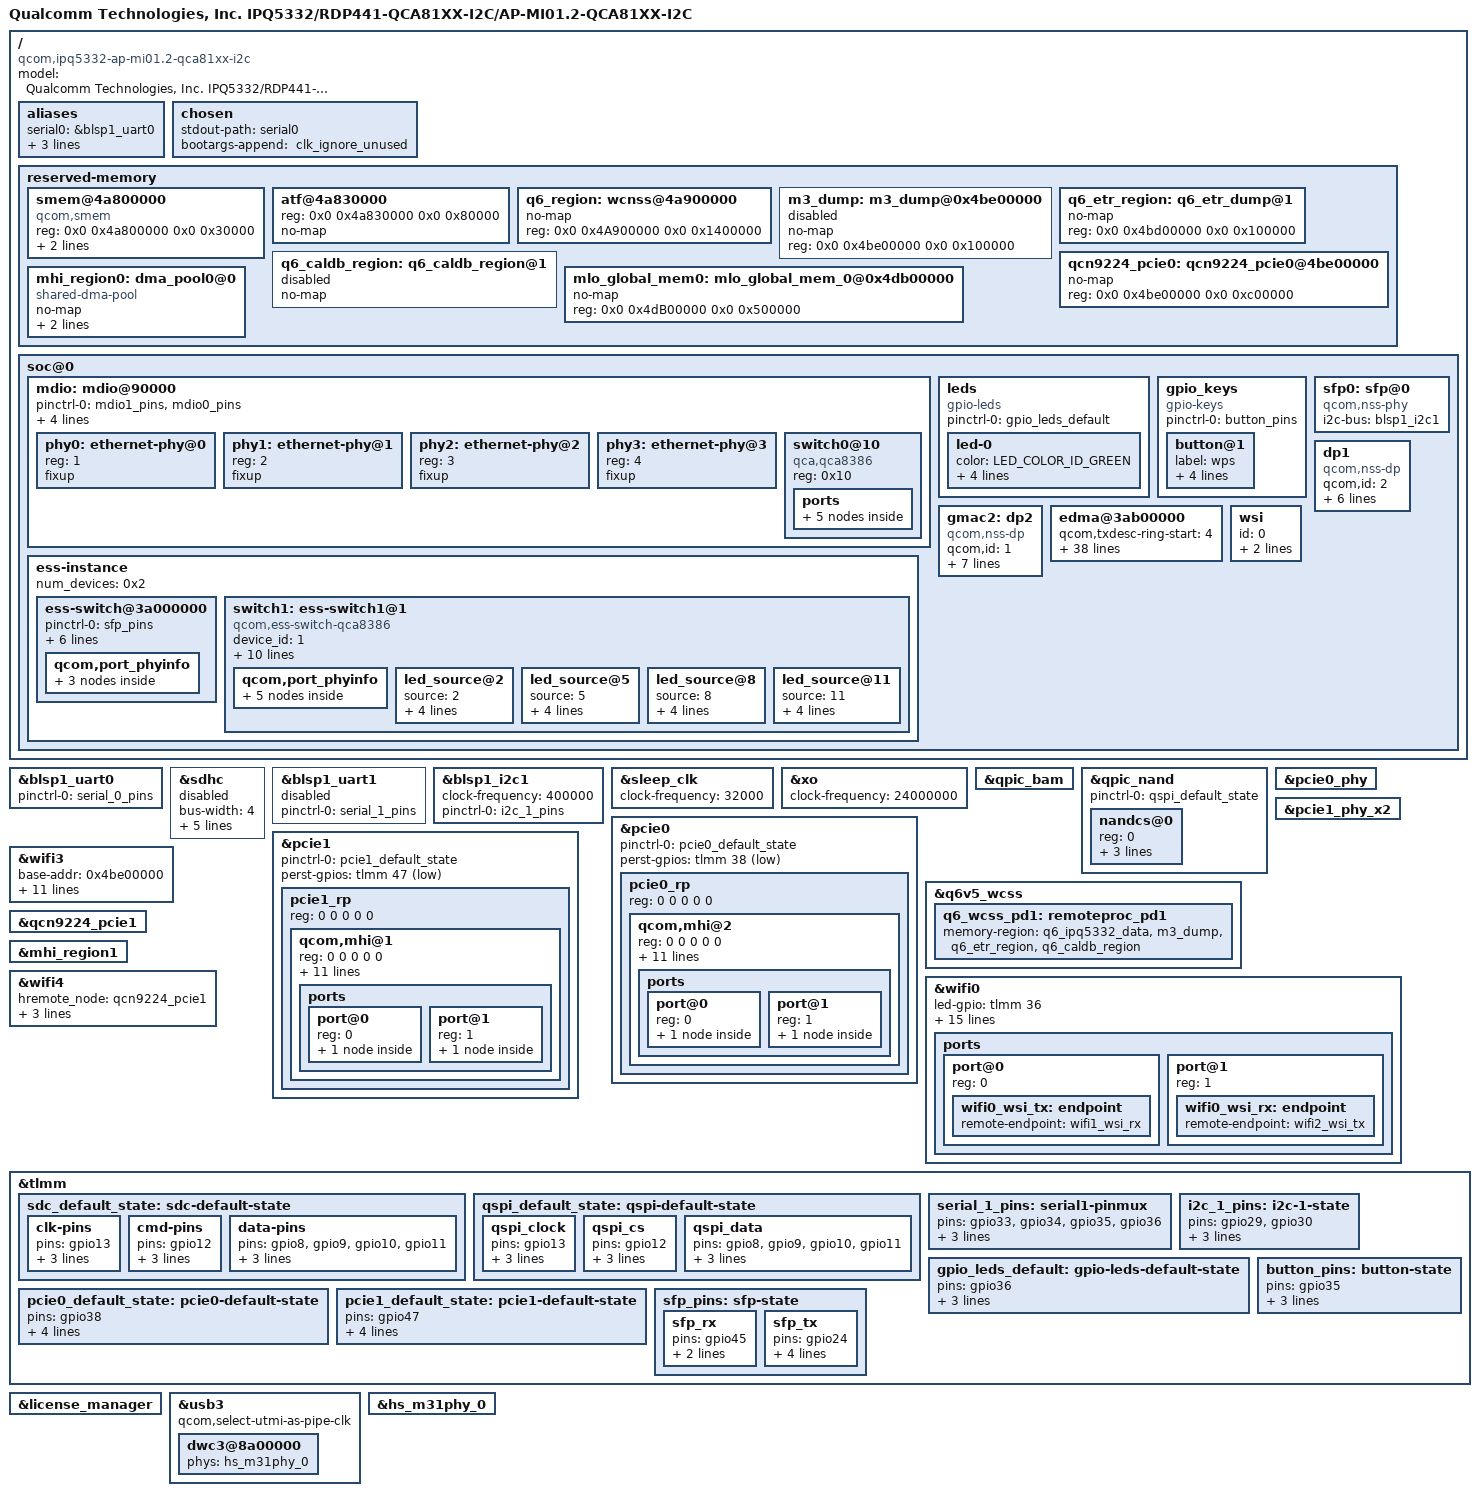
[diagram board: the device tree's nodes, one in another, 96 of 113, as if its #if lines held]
// SPDX-License-Identifier: BSD-3-Clause
/*
 * IPQ5332 AP-MI01.2-QCA81XX-I2C board device tree source
 *
 * Copyright (c) 2022-2025 Qualcomm Innovation Center, Inc. All rights reserved.
 */

/dts-v1/;

#include <dt-bindings/gpio/gpio.h>
#include <dt-bindings/input/input.h>
#include <dt-bindings/leds/common.h>
#include "ipq5332.dtsi"
#ifdef __IPQ_MEM_PROFILE_512_MB__
#include "ipq5332-512MB-memory.dtsi"
#elif !defined(__IPQ_MEM_PROFILE_256_MB__)
#include "ipq5332-default-memory.dtsi"
#endif

/ {
	model = "Qualcomm Technologies, Inc. IPQ5332/RDP441-QCA81XX-I2C/AP-MI01.2-QCA81XX-I2C";
	compatible = "qcom,ipq5332-ap-mi01.2-qca81xx-i2c", "qcom,ipq5332-rdp441-qca81xx-i2c", "qcom,ipq5332";

	aliases {
		serial0 = &blsp1_uart0;
		serial1 = &blsp1_uart1;
		ethernet0 = "/soc/dp1";
		ethernet1 = "/soc/dp2";
	};

	chosen {
		stdout-path = "serial0";
		bootargs-append = " clk_ignore_unused";
	};

#if defined(__IPQ_MEM_PROFILE_256_MB__)
	/*	  256MB Profile for IPQ5322 + QCN9224
	 * +=========+==============+========================+
	 * |        |              |                         |
	 * | Region | Start Offset |          Size           |
	 * |        |              |                         |
	 * +--------+--------------+-------------------------+
	 * |  SMEM  |  0x4A800000  |          192KB          |
	 * +--------+--------------+-------------------------+
	 * |  ATF   |  0x4A830000  |          512KB          |
	 * +--------+--------------+-------------------------+
	 * |       320 KB not-reserved, used by linux        |
	 * +--------+--------------+-------------------------+
	 * | WLAN   |              |                         |
	 * |   Q6   |  0x4A900000  |          20MB           |
	 * +--------+--------------+-------------------------+
	 * |  QDSS  |  0x4BD00000  |           1MB           |
	 * +--------+--------------+-------------------------+
	 * |  WKK0  |  0x4BE00000  |          12MB           |
	 * +--------+--------------+-------------------------+
	 * |       17 MB not-reserved, used by linux         |
	 * +--------+--------------+-------------------------+
	 * |  MLO   |  0x4DB00000  |           5MB           |
	 * +--------+--------------+-------------------------+
	 * |  MHI0  |    DYNAMIC   |           9MB           |
	 * +=================================================+
	 * |                                                 |
	 * |                                                 |
	 * |            Rest of memory for Linux             |
	 * |                                                 |
	 * |                                                 |
	 * +=================================================+
	 */

	reserved-memory {
		/delete-node/ bootloader@4a300000;
		/delete-node/ sbl@4a500000;

		smem@4a800000 {
			compatible = "qcom,smem";
			reg = <0x0 0x4a800000 0x0 0x30000>;
			no-map;
			hwlocks = <&tcsr_mutex 3>;
		};

		atf@4a830000 {
			reg = <0x0 0x4a830000 0x0 0x80000>;
			no-map;
		};

		q6_region: wcnss@4a900000 {
			no-map;
			reg = <0x0 0x4A900000 0x0 0x1400000>;
		};

		m3_dump: m3_dump@0x4be00000 {
			no-map;
			reg = <0x0 0x4be00000 0x0 0x100000>;
			status = "disabled";
		};

		q6_etr_region: q6_etr_dump@1 {
			no-map;
			reg = <0x0 0x4bd00000 0x0 0x100000>;
		};

		q6_caldb_region:q6_caldb_region@1 {
			no-map;
			status = "disabled";
		};

		qcn9224_pcie0: qcn9224_pcie0@4be00000 {
			no-map;
			reg = <0x0 0x4be00000 0x0 0xc00000>;
		};

		mlo_global_mem0: mlo_global_mem_0@0x4db00000 {
			no-map;
			reg = <0x0 0x4dB00000 0x0 0x500000>;
		};

		mhi_region0: dma_pool0@0 {
			compatible = "shared-dma-pool";
			no-map;
			size = <0x0 0x900000>;
			alignment = <0x0 0x1000>;
		};
	};
#endif

	soc@0 {
		mdio:mdio@90000 {
			pinctrl-0 = <&mdio1_pins &mdio0_pins>;
			pinctrl-names = "default";
			/*gpio51 for manhattan reset*/
			phy-reset-gpio = <&tlmm 51 GPIO_ACTIVE_LOW>;
			phyaddr_fixup = <0xC90F018>;
			uniphyaddr_fixup = <0xC90F014>;
			mdio_clk_fixup; /* MDIO clock sequence fix up flag */
			status = "okay";

			phy0: ethernet-phy@0 {
				reg = <1>;
				fixup;
			};
			phy1: ethernet-phy@1 {
				reg = <2>;
				fixup;
			};
			phy2: ethernet-phy@2 {
				reg = <3>;
				fixup;
			};
			phy3: ethernet-phy@3 {
				reg = <4>;
				fixup;
			};

			switch0@10 {
				compatible = "qca,qca8386";
				#address-cells = <1>;
				#size-cells = <0>;
				reg = <0x10>;

				ports {
					#address-cells = <1>;
					#size-cells = <0>;

					port@0 {
						reg = <0>;
						label = "cpu";
						ethernet = <&gmac2>;
						dsa-tag-protocol = "qca_8021q";
					};

					port@1 {
						reg = <1>;
						label = "lan1";
						phy-handle = <&phy0>;
						phy-mode = "internal";
					};

					port@2 {
						reg = <2>;
						label = "lan2";
						phy-handle = <&phy1>;
						phy-mode = "internal";
					};

					port@3 {
						reg = <3>;
						label = "lan3";
						phy-handle = <&phy2>;
						phy-mode = "internal";
					};

					port@4 {
						reg = <4>;
						label = "lan4";
						phy-handle = <&phy3>;
						phy-mode = "internal";
					};
				};
			};
		};

		leds {
			compatible = "gpio-leds";
			pinctrl-0 = <&gpio_leds_default>;
			pinctrl-names = "default";

			led-0 {
				color = <LED_COLOR_ID_GREEN>;
				function = LED_FUNCTION_WLAN;
				gpios = <&tlmm 36 GPIO_ACTIVE_HIGH>;
				linux,default-trigger = "phy0tx";
				default-state = "off";
			};
		};

		gpio_keys {
			compatible = "gpio-keys";
			pinctrl-0 = <&button_pins>;
			pinctrl-names = "default";
			status = "okay";

			button@1 {
				label = "wps";
				linux,code = <KEY_WPS_BUTTON>;
				gpios = <&tlmm 35 GPIO_ACTIVE_LOW>;
				linux,input-type = <1>;
				debounce-interval = <60>;
			};
		};

		sfp0: sfp@0 {
			status = "okay";
			compatible = "qcom,nss-phy";
			i2c-bus = <&blsp1_i2c1>;
		};

		ess-instance {
			num_devices = <0x2>;

			ess-switch@3a000000 {
				pinctrl-0 = <&sfp_pins>;
				pinctrl-names = "default";
				switch_cpu_bmp = <0x1>;  /* cpu port bitmap */
				switch_lan_bmp = <0x2>; /* lan port bitmap */
				switch_wan_bmp = <0x4>; /* wan port bitmap */
				switch_mac_mode = <0xc>; /* mac mode for uniphy instance0*/
				switch_mac_mode1 = <0xe>; /* mac mode for uniphy instance1*/
				switch_mac_mode2 = <0xff>; /* mac mode for uniphy instance2*/

				qcom,port_phyinfo {
					port@0 {
						port_id = <1>;
						forced-speed = <2500>;
						forced-duplex = <1>;
						switch_external {
							switch_handle = <&switch1>;
							switch_cpu_port = <0>;
						};
					};
					port@1 {
						port_id = <2>;
						media-type = "sfp"; /* fiber mode */
						i2c-bus = <&blsp1_i2c1>;
					};
				};
			};

			switch1: ess-switch1@1 {
				compatible = "qcom,ess-switch-qca8386";
				device_id = <1>;
				switch_access_mode = "mdio";
				mdio-bus = <&mdio>;
				switch_mac_mode = <0xc>; /* mac mode for uniphy instance0 */
				switch_mac_mode1 = <0xff>; /* mac mode1 for uniphy instance1 */
				switch_cpu_bmp = <0x1>;  /* cpu port bitmap */
				switch_lan_bmp = <0x1e>; /* lan port bitmap */
				switch_wan_bmp = <0x0>;  /* wan port bitmap */
				link-polling-required = <0>;
				fdb_sync = "interrupt";
				link-intr-gpio = <&tlmm 23 GPIO_ACTIVE_HIGH>;

				qcom,port_phyinfo {
					port@0 {
						port_id = <0>;
						forced-speed = <2500>;
						forced-duplex = <1>;
					};
					port@1 {
						port_id = <1>;
						phy_address = <1>;
					};
					port@2 {
						port_id = <2>;
						phy_address = <2>;
					};
					port@3 {
						port_id = <3>;
						phy_address = <3>;
					};
					port@4 {
						port_id = <4>;
						phy_address = <4>;
					};
				};

				led_source@2 {
					source = <2>;
					mode = "normal";
					speed = "all";
					blink_en = "enable";
					active = "high";
				};
				led_source@5 {
					source = <5>;
					mode = "normal";
					speed = "all";
					blink_en = "enable";
					active = "high";
				};
				led_source@8 {
					source = <8>;
					mode = "normal";
					speed = "all";
					blink_en = "enable";
					active = "high";
				};
				led_source@11 {
					source = <11>;
					mode = "normal";
					speed = "all";
					blink_en = "enable";
					active = "high";
				};
			};
		};

		dp1 {
			device_type = "network";
			compatible = "qcom,nss-dp";
			qcom,id = <2>;
			reg = <0x3a504000 0x4000>;
			qcom,mactype = <1>;
			local-mac-address = [000000000000];
			i2c-bus = <&blsp1_i2c1>;
			qcom,link-poll = <1>;
			phy-mode = "sgmii";
		};

		gmac2:dp2 {
			device_type = "network";
			compatible = "qcom,nss-dp";
			qcom,id = <1>;
			reg = <0x3a500000 0x4000>;
			qcom,mactype = <1>;
			local-mac-address = [000000000000];
			phy-mode = "sgmii";
			qcom,mht-dev = <1>;
			qcom,is_switch_connected = <1>;
			qcom,ppe-offload-disabled = <1>;
		};

		/* EDMA host driver configuration for the board */
		edma@3ab00000 {
			qcom,txdesc-ring-start = <4>;		/* Tx desc ring start ID */
			qcom,txdesc-rings = <12>;		/* Total number of Tx desc rings to be provisioned */
			qcom,mht-txdesc-rings = <8>;            /* Extra Tx desc rings to be provisioned for MHT SW ports */
			qcom,txcmpl-ring-start = <4>;		/* Tx complete ring start ID */
			qcom,txcmpl-rings = <12>;		/* Total number of Tx complete rings to be provisioned */
			qcom,mht-txcmpl-rings = <8>;            /* Extra Tx complete rings to be provisioned for mht sw ports. */
			qcom,rxfill-ring-start = <4>;		/* Rx fill ring start ID */
			qcom,rxfill-rings = <4>;		/* Total number of Rx fill rings to be provisioned */
			qcom,rxdesc-ring-start = <12>;		/* Rx desc ring start ID */
			qcom,rxdesc-rings = <4>;		/* Total number of Rx desc rings to be provisioned */
			qcom,rx-page-mode = <0>;		/* Rx fill ring page mode */
			qcom,tx-map-priority-level = <1>;	/* Tx priority level per port */
			qcom,rx-map-priority-level = <1>;	/* Rx priority level per core */
			qcom,num_loopback_rings = <1>;
			qcom,txdesc_loopback_ring_id = <0>;
			qcom,txcmpl_loopback_ring_id = <0>;
			qcom,rxfill_loopback_ring_id = <0>;
			qcom,rxdesc_loopback_ring_id = <0>;
			qcom,loopback_queue_base = <56>;
			qcom,loopback_num_queues = <8>;
			qcom,ppeds-num = <2>;			/* Number of PPEDS nodes */
			/* PPE-DS node format: <Rx-fill Tx-cmpl Rx Tx Queue-base Queue-count> */
			qcom,ppeds-map = <1 1 1 1 32 8>,	/* PPEDS Node#0 ring and queue map */
					<2 2 2 2 40 8>;		/* PPEDS Node#1 ring and queue map */
			qcom,txdesc-map = <8 9 10 11>,		/* Port0 per-core Tx ring map */
					<12 13 14 15>,        /* MHT-Port1 per-core Tx ring map */
					<4 5 6 7>,            /* MHT-Port2 per-core Tx ring map/packets from  vp*/
					<16 17 18 19>,        /* MHT-Port3 per-core Tx ring map */
					<20 21 22 23>;        /* MHT-Port4 per-core Tx ring map */
			qcom,txdesc-fc-grp-map = <1 2 3 4 5>;   /* Per GMAC flow control group map */
			qcom,rxfill-map = <4 5 6 7>;		/* Per-core Rx fill ring map */
			qcom,rxdesc-map = <12 13 14 15>;	/* Per-core Rx desc ring map */
			qcom,rx-queue-start = <0>;		/* Rx queue start */
			qcom,rx-ring-queue-map = <0 8 16 24>,	/* Priority 0 queues per-core Rx ring map */
						<1 9 17 25>,	/* Priority 1 queues per-core Rx ring map */
						<2 10 18 26>,	/* Priority 2 queues per-core Rx ring map */
						<3 11 19 27>,	/* Priority 3 queues per-core Rx ring map */
						<4 12 20 28>,	/* Priority 4 queues per-core Rx ring map */
						<5 13 21 29>,	/* Priority 5 queues per-core Rx ring map */
						<6 14 22 30>,	/* Priority 6 queues per-core Rx ring map */
						<7 15 23 31>;	/* Priority 7 queues per-core Rx ring map */
			interrupts = <0 163 4>,			/* Tx complete ring id #4 IRQ info */
				   <0 164 4>,			/* Tx complete ring id #5 IRQ info */
				   <0 165 4>,			/* Tx complete ring id #6 IRQ info */
				   <0 166 4>,			/* Tx complete ring id #7 IRQ info */
				   <0 167 4>,			/* Tx complete ring id #8 IRQ info */
				   <0 168 4>,			/* Tx complete ring id #9 IRQ info */
				   <0 169 4>,			/* Tx complete ring id #10 IRQ info */
				   <0 170 4>,			/* Tx complete ring id #11 IRQ info */
				   <0 171 4>,			/* Tx complete ring id #12 IRQ info */
				   <0 172 4>,			/* Tx complete ring id #13 IRQ info */
				   <0 173 4>,			/* Tx complete ring id #14 IRQ info */
				   <0 174 4>,			/* Tx complete ring id #15 IRQ info */
				   <0 139 4>,			/* Rx desc ring id #12 IRQ info */
				   <0 140 4>,			/* Rx desc ring id #13 IRQ info */
				   <0 141 4>,			/* Rx desc ring id #14 IRQ info */
				   <0 142 4>,			/* Rx desc ring id #15 IRQ info */
				   <0 191 4>,			/* Misc error IRQ info */
				   <0 155 4>,			/* RxFill ring id #4 IRQ info */
				   <0 156 4>,			/* RxFill ring id #5 IRQ info */
				   <0 157 4>,			/* RxFill ring id #6 IRQ info */
				   <0 158 4>,			/* RxFill ring id #7 IRQ info */
				<0 160 4>,			/* PPEDS Node #1(TxComp ring id #1) TxComplete IRQ info */
				<0 128 4>,			/* PPEDS Node #1(Rx Desc ring id #1) Rx Desc IRQ info */
				<0 152 4>,			/* PPEDS Node #1(RxFill Desc ring id #1) Rx Fill IRQ info */
				<0 161 4>,			/* PPEDS Node #2(TxComp ring id #2) TxComplete IRQ info */
				<0 129 4>,			/* PPEDS Node #2(Rx Desc ring id #2) Rx Desc IRQ info */
				<0 153 4>,                      /* PPEDS Node #2(RxFill Desc ring id #2) Rx Fill IRQ info */
				<0 175 4>,                   /* MHT port Tx complete ring id #16 IRQ info */
				<0 176 4>,                   /* MHT port Tx complete ring id #17 IRQ info */
				<0 177 4>,                   /* MHT port Tx complete ring id #18 IRQ info */
				<0 178 4>,                   /* MHT port Tx complete ring id #19 IRQ info */
				<0 179 4>,                   /* MHT port Tx complete ring id #20 IRQ info */
				<0 180 4>,                   /* MHT port Tx complete ring id #21 IRQ info */
				<0 181 4>,                   /* MHT port Tx complete ring id #22 IRQ info */
				<0 182 4>;                   /* MHT port Tx complete ring id #23 IRQ info */
		};

		wsi: wsi {
			id = <0>;
			num_chip = <3>;
			status = "okay";
			chip_info = <0 2 1 2>,
				    <1 2 2 0>,
				    <2 2 0 1>;
		};
	};
};

&blsp1_uart0 {
	pinctrl-0 = <&serial_0_pins>;
	pinctrl-names = "default";
	status = "okay";
};

&sdhc {
	bus-width = <4>;
	max-frequency = <192000000>;
	mmc-ddr-1_8v;
	mmc-hs200-1_8v;
	non-removable;
	pinctrl-0 = <&sdc_default_state>;
	pinctrl-names = "default";
	status = "disabled";
};

&blsp1_uart1 {
	pinctrl-0 = <&serial_1_pins>;
	pinctrl-names = "default";
	status = "disabled";
};

&blsp1_i2c1 {
	clock-frequency  = <400000>;
	pinctrl-0 = <&i2c_1_pins>;
	pinctrl-names = "default";
	status = "okay";
};

&sleep_clk {
	clock-frequency = <32000>;
};

&xo {
	clock-frequency = <24000000>;
};

&qpic_bam {
	status = "okay";
};

&qpic_nand {
	pinctrl-0 = <&qspi_default_state>;
	pinctrl-names = "default";
	status = "okay";

	nandcs@0 {
		reg = <0>;
		#address-cells = <1>;
		#size-cells = <1>;

		nand-ecc-strength = <8>;
		nand-ecc-step-size = <512>;
		nand-bus-width = <8>;
	};
};

&pcie0_phy {
	status = "okay";
};

&pcie0 {
	pinctrl-0 = <&pcie0_default_state>;
	pinctrl-names = "default";
	perst-gpios = <&tlmm 38 GPIO_ACTIVE_LOW>;
	status = "okay";

	pcie0_rp {
		reg = <0 0 0 0 0>;

		qcom,mhi@2 {
			reg = <0 0 0 0 0>;
			boot-args = <0x2 0x4 0x34 0x3 0x0 0x0     /* MX Rail, GPIO52, Drive strength 0x3 */
					0x4 0x4 0x18 0x3 0x0 0x0  /* RFA1p2 Rail, GPIO24, Drive strength 0x3 */
					0x0 0x4 0x0 0x0 0x0 0x0>; /* End of arguments */
			memory-region = <&qcn9224_pcie0>, <&mhi_region0>, <&mlo_global_mem0>;
			memory-region-names = "host-ddr-mem", "mhi-region", "mlo-global-mem";
			qcom,early_cal_enabled = "supported";
			qcom,caldata_offset = <0x26800>;
			qcom,board_id = <0x15>;
			qcom,wsi = <&wsi>;
			qcom,wsi_index = <1>;
			ports {
				#address-cells = <1>;
				#size-cells = <0>;

				port@0 {
					reg = <0>;

					wifi1_wsi_tx: endpoint {
						remote-endpoint = <&wifi2_wsi_rx>;
					};
				};

				port@1 {
					reg = <1>;

					wifi1_wsi_rx: endpoint {
						remote-endpoint = <&wifi0_wsi_tx>;
					};
				};
			};
		};
	};
};

&pcie1_phy_x2 {
#if !defined(__IPQ_MEM_PROFILE_256_MB__) && !defined(__IPQ_MEM_PROFILE_512_MB__)
	status = "okay";
#else
	status = "disabled";
#endif
};

&pcie1 {
	pinctrl-0 = <&pcie1_default_state>;
	pinctrl-names = "default";
	perst-gpios = <&tlmm 47 GPIO_ACTIVE_LOW>;
	status = "okay";

	pcie1_rp {
		reg = <0 0 0 0 0>;

		qcom,mhi@1 {
			reg = <0 0 0 0 0>;
			boot-args = <0x2 0x4 0x34 0x3 0x0 0x0     /* MX Rail, GPIO52, Drive strength 0x3 */
					0x4 0x4 0x18 0x3 0x0 0x0  /* RFA1p2 Rail, GPIO24, Drive strength 0x3 */
					0x0 0x4 0x0 0x0 0x0 0x0>; /* End of arguments */
#if !defined(__IPQ_MEM_PROFILE_256_MB__) && !defined(__IPQ_MEM_PROFILE_512_MB__)
			memory-region = <&qcn9224_pcie1>, <&mhi_region1>, <&mlo_global_mem0>;
			memory-region-names = "host-ddr-mem", "mhi-region", "mlo-global-mem";
			qcom,early_cal_enabled = "supported";
			qcom,caldata_offset = <0x58800>;
#endif
			qcom,board_id = <0x16>;
			qcom,wsi = <&wsi>;
			qcom,wsi_index = <2>;
			ports {
				#address-cells = <1>;
				#size-cells = <0>;

				port@0 {
					reg = <0>;

					wifi2_wsi_tx: endpoint {
						remote-endpoint = <&wifi0_wsi_rx>;
					};
				};

				port@1 {
					reg = <1>;

					wifi2_wsi_rx: endpoint {
						remote-endpoint = <&wifi1_wsi_tx>;
					};
				};
			};
		};
	};
};

#if !defined(__IPQ_MEM_PROFILE_256_MB__) && !defined(__IPQ_MEM_PROFILE_512_MB__)
&q6v5_wcss {
	q6_wcss_pd1: remoteproc_pd1 {
		memory-region = <&q6_ipq5332_data>,
				<&m3_dump>,
				<&q6_etr_region>,
				<&q6_caldb_region>;
	};
};

#endif

&wifi0 {
	led-gpio = <&tlmm 36 GPIO_ACTIVE_HIGH>;
#if defined(__RPROC_DISABLE_MPD_SUPPORT__)
	qcom,rproc = <&q6v5_wcss>;
	dump-region = <&q6_ipq5332_data>,
		<&m3_dump>,
#if !defined(__IPQ_MEM_PROFILE_256_MB__)
		<&q6_etr_region>,
		<&q6_caldb_region>;
#endif
#else
	qcom,rproc = <&q6_wcss_pd1>;
	qcom,rproc_rpd = <&q6v5_wcss>;
	qcom,multipd_arch;
#endif
	qcom,userpd-subsys-name = "q6v5_wcss_userpd1";
#if defined(__IPQ_MEM_PROFILE_256_MB__)
	memory-region = <&q6_region>, <&q6_region>, <&mlo_global_mem0>;
	memory-region-names = "q6-region", "q6-region-1", "mlo-global-mem";
#else
	memory-region = <&q6_region>, <&q6_region>, <&q6_ipq5332_data>, <&m3_dump>,
		<&mlo_global_mem0>,<&q6_etr_region>;
	memory-region-names = "q6-region", "q6-1region-1", "host-ddr-mem", "m3-dump",
		"mlo-global-mem", "q6-etr-dump";
#endif
	qcom,wsi = <&wsi>;
	qcom,wsi_index = <0>;
	qcom,wsi-controller;
	qcom,board_id = <0x12>;
	qcom,bdf-addr = <0x4B500000 0x4B500000 0x4B240000 0x0 0x0 0x0>;
	hw_link_id = <0 0>;
	status = "okay";
	ports {
		#address-cells = <1>;
		#size-cells = <0>;

		port@0 {
			reg = <0>;

			wifi0_wsi_tx: endpoint {
				remote-endpoint = <&wifi1_wsi_rx>;
			};
		};

		port@1 {
			reg = <1>;

			wifi0_wsi_rx: endpoint {
				remote-endpoint = <&wifi2_wsi_tx>;
			};
		};
	};
};

&qcn9224_pcie0 {
	status = "okay";
};

#if defined(__MHI_BUS_RESERVED_DMA_POOL__)
&mhi_region0 {
	status = "okay";
};
#endif

&wifi3 {
	/* QCN9224 radio 5G */
#if defined(__IPQ_MEM_PROFILE_256_MB__)
	/* qcn9224 tgt-mem-mode=2 layout - 12MB
	 * +=========+==============+=========+
	 * |  Region | Start Offset |   Size  |
	 * +---------+--------------+---------+
	 * | HREMOTE |  0x4be00000  |   8MB   |
	 * +---------+--------------+---------+
	 * |   ETR   |  0x4c600000  |   1MB   |
	 * +---------+--------------+---------+
	 * |Pageable |  0x4c700000  |   3MB   |
	 * +==================================+
	 */
	base-addr = <0x4be00000>;
	m3-dump-addr = <0>;
	etr-addr = <0x4c600000>;
	pageable-addr = <0x4c700000>;
	hremote-size = <0x800000>;
	pageable-size = <0x300000>;
	caldb-size = <0>;
	tgt-mem-mode = <0x2>;
#endif
	hremote_node = <&qcn9224_pcie0>;
	board_id = <0x15>;
	node_id = <0x0>;
	hw_link_id = <1 0>;
	status = "okay";
};

#if !defined(__IPQ_MEM_PROFILE_256_MB__) && !defined(__IPQ_MEM_PROFILE_512_MB__)
&qcn9224_pcie1 {
	status = "ok";
};

#if defined(__MHI_BUS_RESERVED_DMA_POOL__)
&mhi_region1 {
	status = "ok";
};
#endif

&wifi4 {
	/* QCN9224 radio 6G */
	hremote_node = <&qcn9224_pcie1>;
	board_id = <0x16>;
	node_id = <0x1>;
	hw_link_id = <2 0>;
	status = "okay";
};
#endif
/* PINCTRL */

&tlmm {
	sdc_default_state: sdc-default-state {
		clk-pins {
			pins = "gpio13";
			function = "sdc_clk";
			drive-strength = <8>;
			bias-disable;
		};

		cmd-pins {
			pins = "gpio12";
			function = "sdc_cmd";
			drive-strength = <8>;
			bias-pull-up;
		};

		data-pins {
			pins = "gpio8", "gpio9", "gpio10", "gpio11";
			function = "sdc_data";
			drive-strength = <8>;
			bias-pull-up;
		};
	};

	qspi_default_state: qspi-default-state {
		qspi_clock {
			pins = "gpio13";
			function = "qspi_clk";
			drive-strength = <8>;
			bias-pull-down;
		};

		qspi_cs {
			pins = "gpio12";
			function = "qspi_cs";
			drive-strength = <8>;
			bias-pull-up;
		};

		qspi_data {
			pins = "gpio8", "gpio9", "gpio10", "gpio11";
			function = "qspi_data";
			drive-strength = <8>;
			bias-pull-down;
		};
	};

	serial_1_pins: serial1-pinmux {
		pins = "gpio33", "gpio34", "gpio35", "gpio36";
		function = "blsp1_uart2";
		drive-strength = <8>;
		bias-pull-up;
	};

	i2c_1_pins: i2c-1-state {
		pins = "gpio29", "gpio30";
		function = "blsp1_i2c0";
		drive-strength = <8>;
		bias-pull-up;
	};

	gpio_leds_default: gpio-leds-default-state {
		pins = "gpio36";
		function = "gpio";
		drive-strength = <8>;
		bias-pull-down;
	};

	button_pins: button-state {
		pins = "gpio35";
		function = "gpio";
		drive-strength = <8>;
		bias-pull-up;
	};

	pcie0_default_state: pcie0-default-state {
		pins = "gpio38";
		function = "gpio";
		drive-strength = <8>;
		bias-pull-up;
		output-low;
	};

	pcie1_default_state: pcie1-default-state {
		pins = "gpio47";
		function = "gpio";
		drive-strength = <8>;
		bias-pull-up;
		output-low;
	};

	sfp_pins: sfp-state {
		sfp_rx {
			pins = "gpio45";
			function = "rx1";
			bias-disable;
		};
		sfp_tx {
			pins = "gpio24";
			function = "gpio";
			drive-strength = <8>;
			bias-pull-down;
			output-low;
		};
	};

};

&license_manager {
	status = "okay";
};

&usb3 {
	qcom,select-utmi-as-pipe-clk;
	status = "okay";

	dwc3@8a00000 {
		phys = <&hs_m31phy_0>;
		phy-names = "usb2-phy";
	};
};

&hs_m31phy_0 {
	status = "okay";
};
